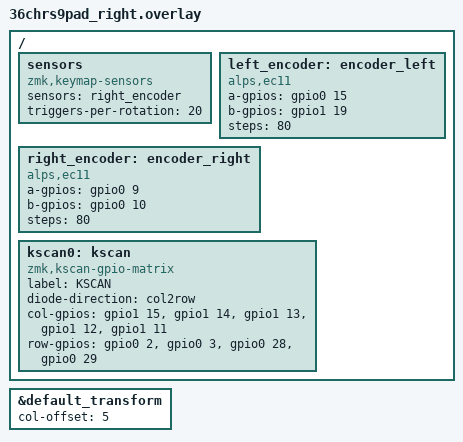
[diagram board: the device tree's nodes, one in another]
#include "36chrs9pad.dtsi" 
#include <dt-bindings/zmk/input_transform.h>
#include <input/processors.dtsi>

&default_transform {
	col-offset = <5>;
}; 
// Encoders
/{
    sensors: sensors {
        compatible = "zmk,keymap-sensors";
        sensors = <
        /*&left_encoder*/ 
        &right_encoder
        >;
        triggers-per-rotation = <20>;
    };
    left_encoder: encoder_left {
        compatible = "alps,ec11";
        a-gpios = <&gpio0 15 (GPIO_ACTIVE_HIGH | GPIO_PULL_UP)>;
        b-gpios = <&gpio1 19 (GPIO_ACTIVE_HIGH | GPIO_PULL_UP)>;
        steps = <80>;
        status = "disabled";
    };
    right_encoder: encoder_right {
        compatible = "alps,ec11";
        a-gpios = <&gpio0 9 (GPIO_ACTIVE_HIGH | GPIO_PULL_UP)>;
        b-gpios = <&gpio0 10 (GPIO_ACTIVE_HIGH | GPIO_PULL_UP)>;
        steps = <80>;
        status = "disabled";
    };
};
&left_encoder {
    status = "okay";
};
&right_encoder {
    status = "okay";
};

/ {
    kscan0: kscan {
        compatible = "zmk,kscan-gpio-matrix";
        label = "KSCAN";
        diode-direction = "col2row";
        // compatible = "zmk,kscan-gpio-matrix";
        // diode-direction = "col2row";
    col-gpios
    	= <&gpio1 15 GPIO_ACTIVE_HIGH>//Col0
        , <&gpio1 14 GPIO_ACTIVE_HIGH>//Col1
        , <&gpio1 13 GPIO_ACTIVE_HIGH>//Col2
        , <&gpio1 12 GPIO_ACTIVE_HIGH>//Col3
        , <&gpio1 11 GPIO_ACTIVE_HIGH>//Col4
        ;
	row-gpios
        = <&gpio0 2 (GPIO_ACTIVE_HIGH | GPIO_PULL_DOWN)>   //Row2
        , <&gpio0 3 (GPIO_ACTIVE_HIGH | GPIO_PULL_DOWN)>   //Row3
        , <&gpio0 28 (GPIO_ACTIVE_HIGH | GPIO_PULL_DOWN)>  //Row0
        , <&gpio0 29 (GPIO_ACTIVE_HIGH | GPIO_PULL_DOWN)>   //Row1
        ;
    };
};

